# netx90_app register map
File version: 1.0
CPU: CM4 r0p1, little endian, MPU, FPU, 4 interrupt priority bits, 78 interrupts
Registers are 32-bit, read-write, reset 0x0 unless marked. A register's access mark holds for its fields unless they carry their own. Offsets are from the block's base; [hi:lo] are bit positions; {n}, {i} and the like mark numbered series; 'fields as' and 'values as' point back to an identical list.

## madc_seq0
Base 0xFF401800
Same registers: madc_seq1 0xFF401900, madc_seq2 0xFF401A00, madc_seq3 0xFF401B00
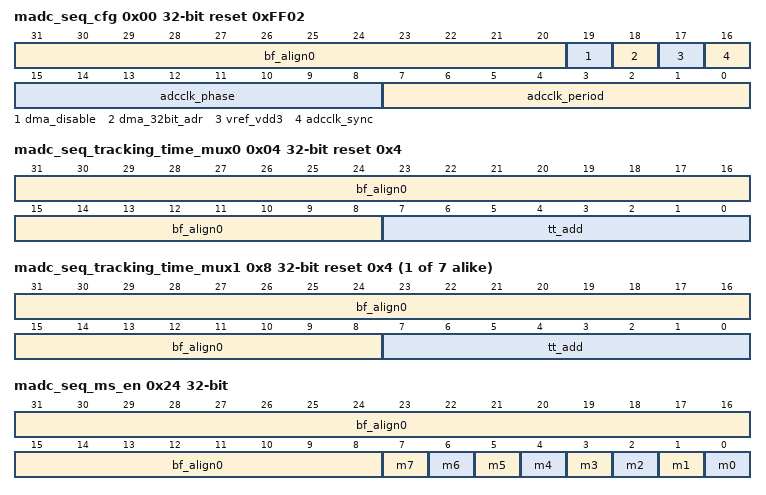
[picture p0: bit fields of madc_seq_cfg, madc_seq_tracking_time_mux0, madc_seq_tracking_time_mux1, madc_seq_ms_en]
0x00 madc_seq_cfg reset 0xFF02 (reset mask 0xFFFFF) — ADC static configuration
  [31:20] bf_align0 — bitField alignment value for aeabi compatibility
  [19] dma_disable — Disable DMA 1: DMA is disabled, results are not written to memory, only the current result will be visible in madc_seq_result_current. 0: DMA is enabled, results are written to memory as defined in madc_seq_ms_adr and madc_seq_m*-adr_offset.
  [18] dma_32bit_adr — The DMA engine only uses 32bit addresses and DWord access. This mode wastes memory but speeds up the DMA access by not running read-modify-write cycles.
  [17] vref_vdd3 — Reference Select of ADC: 0: use reference from pin VREF_ADC (internally driven C or external reference, s. madc_adc01_static_cfg-vref_buffer_enable) 1: use reference from pin VDD3 (Analog core supply)
  [16] adcclk_sync — 0: The rising edges of adcclk are generated independently of the other ADCs. 1: Use adc_clock_phase for defined clock phases in relation to other ADC sequencers
  [15:8] adcclk_phase — Generation of the rising edge of the adcclk is delayed until the global clk_phase counter matches this value. NOTE: The rising edge of the adcclk ending the first sample period of a triggered measurement is NEVER delayed.
  [7:0] adcclk_period — Duration of an adcclk period in system clock cycles-1 For odd values the high phase of adcclk is one system clock cycle longer than the low phase.
0x04 madc_seq_tracking_time_mux0 reset 0x4 (reset mask 0xFF) — ADC sample extension for input channel 0 Length of 2nd adcclk in steps of 10ns system clock(~ delay of 3rd adcclk edge). The capacitor inside ADC needs time to be charged depending on the driving strength of the external signal. For 12 bit precision, a settling to time of 9 tau should be ensured. tau can be calculated by tau = 9*(ADC_MUX_RSER + Rext) * ADC_MUX_CIN, with Rext being additional resistance from devices external to the SOC. The setting of tt_add also depends on the setting of madc_seq_cfg.adcclk_period and can be calculate by the following formula: tt_add = ceil( tau/10ns - madc_seq_cfg.adcclk_period ) - 2 Set tt_add=4 if calculated value is smaller 4. Note: madc_seq_cfg.adcclk_period and madc_seq_tracking_time_mux[x].tt_add will count down to 0 meaning that the value set in the registers is increased by 1. To compensate this the tt_add formula includes a '-2'. Note: ADC_MUX_RSET(1.5kOhm) and ADC_MUX_CIN(10pF) are defined in the electrical parameters. The total ADC cycle time results in: tcycle = 14 * adcclk_period + clock_sync_delay (max 1 adcclk_period) + tt_add * 10ns.
  [31:8] bf_align0 — bitField alignment value for aeabi compatibility
  [7:0] tt_add — Tracking time addon
{0x4+4i} madc_seq_tracking_time_mux{i} reset 0x4 (reset mask 0xFF) (i=1..7) — ADC sample extension for input channel {i} s. madc_seq_tracking_time_mux0 for details.
  fields as madc_seq_tracking_time_mux0
0x24 madc_seq_ms_en (reset mask 0xFF) — Enable measurement configurations: Terminology: A measurement sequence consists of upto 8 measurements. A measurement consists of up to 8 samples. A sample needs at least 14 adcclk cycles (+ tracking time addon). This register enables the measurements belonging to a measurement sequence (up to 8). With the start of a measurement sequence (s. madc_seq_cmd) all sequence configuration registers (ms_en, ms_adr, m0..m7) are copied to shadow registers that can no longer be changed until the measurement sequence is finished. All further write accesses to these registers will be valid for the subsequent measurement sequence. The software must ensure, that a set of configuration data for one sequence is completely written before starting the next sequence.
  [31:8] bf_align0 — bitField alignment value for aeabi compatibility
  [n] m{n} (n=0..7) — 1: Enable measurement defined by madc_seq_m{n} for the current measurement sequence
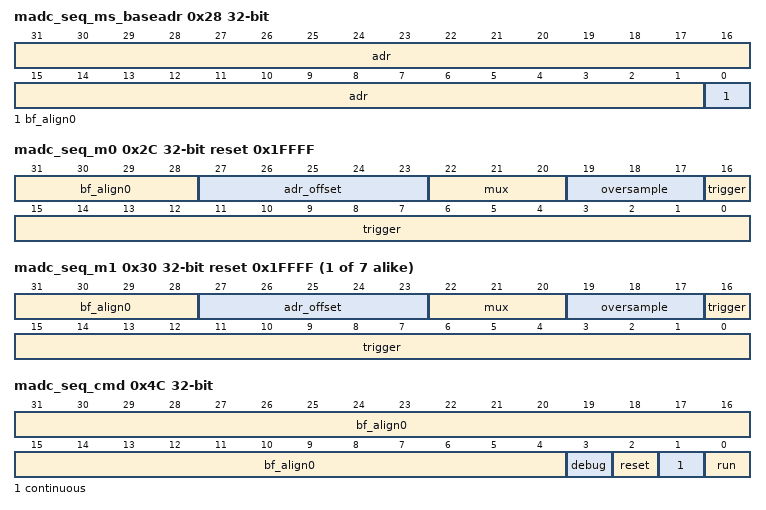
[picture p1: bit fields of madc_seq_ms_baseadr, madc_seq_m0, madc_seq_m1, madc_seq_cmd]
0x28 madc_seq_ms_baseadr (reset mask 0xFFFFFFFE) — Base address for writing the measurement results.
  [31:1] adr — word (16 bit) aligned address, LSB is ignored In case of madc_seq_cfg-dma_32bit_adr=1, bit 1 will be ignored.
  [0] bf_align0 — bitField alignment value for aeabi compatibility
0x2C madc_seq_m0 reset 0x1FFFF (reset mask 0xFFFFFFF) — Measurement 0 configuration: A measurement performs (oversample+1) ADC conversions, summing up the results. Every ADC conversion starts with two adcclk periods followed by a sampling phase extension with a minimal duration selected by sext_sel. The sampling phase of the first ADC conversion of the measurement ends when the trigger condition is fulfilled. All subsequent conversions of the measurement do not wait for any trigger condition. The sum consisting of (oversample+1) ADC conversions is written as a 16 bit word to the memory location (byte address) ms_adr + 2*adr_offset. During the measurement the input multiplexer setting (channel selection) is changed to the value mux. Depending on the timing selected by mux_time_sel the channel setting becomes effective for this or the next measurement.
  [31:28] bf_align0 — bitField alignment value for aeabi compatibility
  [27:23] adr_offset — Address offset specified in 16 bit words where the sum will be stored In case of madc_seq_cfg-dma_32bit_adr=1, this value will be interpreted as 32-bit address.
  [22:20] mux — Input channel multiplexer setting The input multiplexer will always be set 1 system clock (10ns) before SOF. It will be reset after sampling to ensure a not-connected phase at the one-hot-coded multiplexer switches.
  [19:17] oversample — Number of samples minus one to sum for this measurement i.e. 0:sum 1 samples, 1:sum 2 samples, ...
  [16:0] trigger — Trigger condition for measurement 0x0...0x0FFFF: condition (ECNT == trigger) 0x10000...0x10005: delayed DTEVT[0..5]==1 0x10006: GPIO_APP_COUNTER0 = 0 0x10007: GPIO_APP_COUNTER1 = 0 0x10008: GPIO_APP_COUNTER2 = 0 0x10009: posedge of xc_trigger[0] 0x1000a: posedge of xc_trigger[1] 0x1000b: negedge of xc_trigger[0] 0x1000c: negedge of xc_trigger[1] 0x1000d: posedge of xc_sample[0] 0x1000e: posedge of xc_sample[1] 0x1000f: negedge of xc_sample[0] 0x10010: negedge of xc_sample[1] 0x1FFFF: no trigger, measurement executes immediately after end of sampling phase Note: Ensure that the time between SOC and trigger event does not exceed ADC_MAXTRACK (10ms).
{0x2C+4i} madc_seq_m{i} reset 0x1FFFF (reset mask 0xFFFFFFF) (i=1..7) — Measurement {i} configuration: s. madc_seq_m0 for details
  [31:28] bf_align0 — bitField alignment value for aeabi compatibility
  [27:23] adr_offset — Address offset specified in 16 bit words where the sum will be stored
  [22:20] mux — Input channel multiplexer setting
  [19:17] oversample — Number of samples minus one to sum for this measurement
  [16:0] trigger — Trigger condition for measurement
0x4C madc_seq_cmd (reset mask 0xF) — Command Register: Run or abort processing the measurement sequence. This register is writable but can also be changed by hardware (reset).
  [31:4] bf_align0 — bitField alignment value for aeabi compatibility
  [3] debug — Debug mode: 0: ADC is controlled by measurement sequencer 1: ADC is directly controlled by madc_seq_debug register.
  [2] reset — Reset this ADC-sequencer: In comparision to madc_adc01_static_cfg-adc01_reset_n, which resets a pair of ADC channels (e.g. ADC0 and ADC1), this bit only resets this single ADC-sequencer. The analog part of ADC will not be reset, but all registers of the controller (including result registers, which will not be reset in case of run=stop).
  [1] continuous — Continuous mode: 0: run starts single conversion. All measurements enabled in madc_m_en are executed once. 1: start continuous conversion. All measurments enabled are executed repeatedly until stopped by resetting the run bit.
  [0] run — Run bit: This bit can be set here or at madc_start to start all ADCs simultaneously. This bit can be reset here or automatically by hardware, when measurement sequence is finished. 1 : start measurement sequence. 0 : stop measurement sequence. Any conversion in progress is aborted and ADC returns to idle state with adcclk=0 and adc_soc=0.
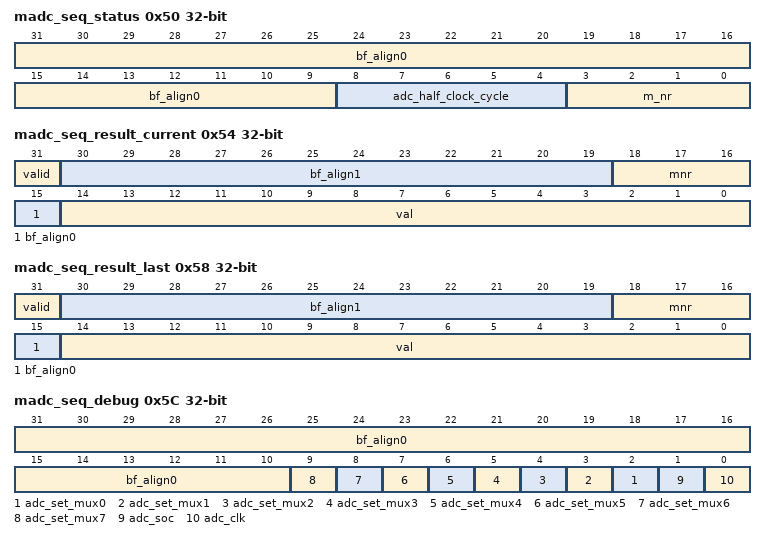
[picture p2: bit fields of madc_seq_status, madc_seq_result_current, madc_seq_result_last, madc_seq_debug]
0x50 madc_seq_status ro (reset mask 0x1FF) — Status of the current measurement sequence in progress
  [31:9] bf_align0 — bitField alignment value for aeabi compatibility
  [8:4] adc_half_clock_cycle — 0..30: current adcclk half clock cycle, 0 when adc is idle
  [3:0] m_nr — Number of measurement configuration: 0..7: currently active measurement configuration, 8 when the ADC is idle
0x54 madc_seq_result_current ro (reset mask 0x80077FFF) — Result register of current measurement
  [31] valid — result in register is finally calculated (val shows intermediate values in case of oversample>0)
  [30:19] bf_align1 — bitField alignment value for aeabi compatibility
  [18:16] mnr — number of measurement configuration
  [15] bf_align0 — bitField alignment value for aeabi compatibility
  [14:0] val — result of measurement
0x58 madc_seq_result_last ro (reset mask 0x80077FFF) — Result register of last measurement
  fields as madc_seq_result_current
0x5C madc_seq_debug (reset mask 0x3FF) — Debug Mode register: If cmd-debug is enabled, this register directly controls inputs of both ADCs. Output data of both ADCs will still be at data0 and data1. In debug mode, a software reset (cfg-reset_n) will not influence these values (only directly signal ADC_NRES).
  [31:10] bf_align0 — bitField alignment value for aeabi compatibility
  [n+2] adc_set_mux{n} (n=0..7) — ADC0_SET_MUX{n} signal
  [1] adc_soc — ADC0_SOC signal
  [0] adc_clk — ADC0 is sampling data.
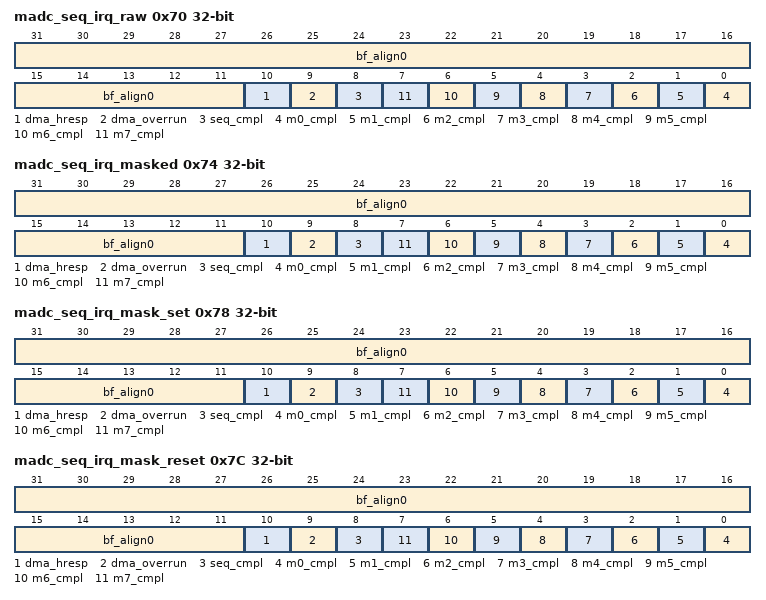
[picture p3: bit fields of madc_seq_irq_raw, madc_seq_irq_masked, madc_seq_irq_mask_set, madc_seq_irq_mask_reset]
0x70 madc_seq_irq_raw (reset mask 0x7FF) — Raw IRQ: Read access shows status of unmasked IRQs. IRQs are set automatically and reset by writing to this register: Write access with '1' resets the appropriate IRQ (if event irq, reset status irqs at their source). Write access with '0' does not influence this bit.
  [31:11] bf_align0 — bitField alignment value for aeabi compatibility
  [10] dma_hresp — AHBL hresp signal received
  [9] dma_overrun — AHBL write buffer overrun result not written due to AHBL busy
  [8] seq_cmpl — measurement sequence completed
  [n] m{n}_cmpl (n=0..7) — event: measurement {n} completed
0x74 madc_seq_irq_masked ro (reset mask 0x7FF) — Masked IRQ: Shows status of masked IRQs (as connected to ARM/xPIC).
  fields as madc_seq_irq_raw
0x78 madc_seq_irq_mask_set (reset mask 0x7FF) — IRQ enable mask: The IRQ mask enables interrupt requests for corresponding interrupt sources. As its bits might be changed by different software tasks, the IRQ mask register is not writable directly, but by set and reset masks: Write access with '1' sets interrupt mask bit. Write access with '0' does not influence this bit. Read access shows actual interrupt mask. Attention: Before activating interrupt mask, delete old pending interrupts by writing the same value to adr_mpwm_irq_raw.
  fields as madc_seq_irq_raw
0x7C madc_seq_irq_mask_reset (reset mask 0x7FF) — IRQ disable mask: This is the corresponding reset mask to disable interrupt requests for corresponding interrupt sources: Write access with '1' resets interrupt mask bit. Write access with '0' does not influence this bit. Read access shows bit number of the lowest active bit in IRQ_MASKED or MAX+1 when no bit is set.
  fields as madc_seq_irq_raw
